# AT32F407xx register map
Vendor: Keil; Series: AT32F407; File version: 1.0
CPU: CM4 r0p1, little endian, no MPU, FPU, 4 interrupt priority bits
Registers are 32-bit, read-write, reset 0x0 unless marked. A register's access mark holds for its fields unless they carry their own. Offsets are from the block's base; [hi:lo] are bit positions.

## Ethernet_PTP — Ethernet: Precision time protocol
Base 0x40028700
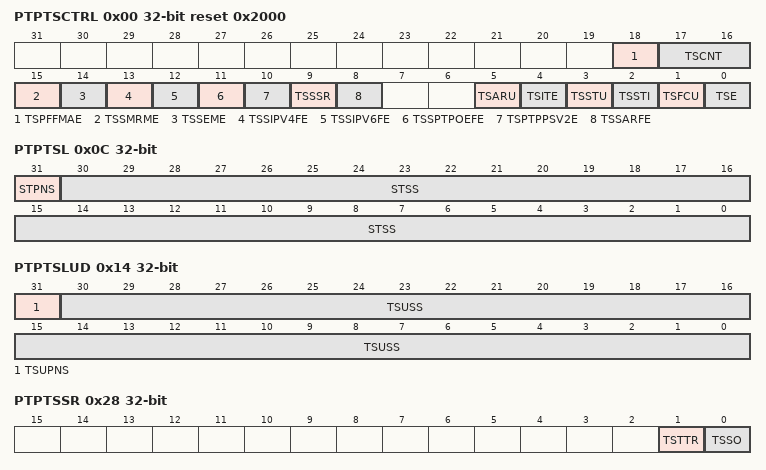
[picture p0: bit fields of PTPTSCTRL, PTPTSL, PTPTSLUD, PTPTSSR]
0x00 PTPTSCTRL reset 0x2000 — Ethernet PTP time stamp control register
  [18] TSPFFMAE — Time stamp PTP frame filtering MAC address enable
  [17:16] TSCNT — Time stamp clock node type
  [15] TSSMRME — Time stamp snapshot for message relevant to master enable
  [14] TSSEME — Time stamp snapshot for event message enable
  [13] TSSIPV4FE — Time stamp snapshot for IPv4 frames enable
  [12] TSSIPV6FE — Time stamp snapshot for IPv6 frames enable
  [11] TSSPTPOEFE — Time stamp snapshot for PTP over ethernet frames enable
  [10] TSPTPPSV2E — Time stamp PTP packet snooping for version2 format enable
  [9] TSSSR — Time stamp subsecond rollover: digital or binary rollover control
  [8] TSSARFE — Time stamp snapshot for all received frames enable
  [5] TSARU — Time stamp addend register update
  [4] TSITE — Time stamp interrupt trigger enable
  [3] TSSTU — Time stamp system time update
  [2] TSSTI — Time stamp system time initialize
  [1] TSFCU — Time stamp fine or coarse update
  [0] TSE — Time stamp enable
0x04 PTPSSINC — Ethernet PTP subsecond increment register
  [7:0] STSINC — System time subsecond increment
0x08 PTPTSH ro — Ethernet PTP time stamp high register
  [31:0] STS — System time second
0x0C PTPTSL ro — Ethernet PTP time stamp low register
  [31] STPNS — System time positive or negative sign
  [30:0] STSS — System time subseconds
0x10 PTPTSHUD — Ethernet PTP time stamp high update register
  [31:0] TSUS — Time stamp update second
0x14 PTPTSLUD — Ethernet PTP time stamp low update register
  [31] TSUPNS — Time stamp update positive or negative sign
  [30:0] TSUSS — Time stamp update subseconds
0x18 PTPTSAD — Ethernet PTP time stamp addend register
  [31:0] TSA — Time stamp addend
0x1C PTPTTH — Ethernet PTP target time high register
  [31:0] TTSH — Target time stamp high
0x20 PTPTTL — Ethernet PTP target time low register
  [31:0] TTSL — Target time stamp low
0x28 PTPTSSR ro — Ethernet PTP time stamp status register
  [1] TSTTR — Time stamp target time reached
  [0] TSSO — Time stamp second overflow
0x2C PTPPPSCR ro — Ethernet PTP PPS control register
  [3:0] PPSFREQ — PPS frequency selection

## ETHERNET_DMA — Ethernet: DMA controller operation
Base 0x40029000
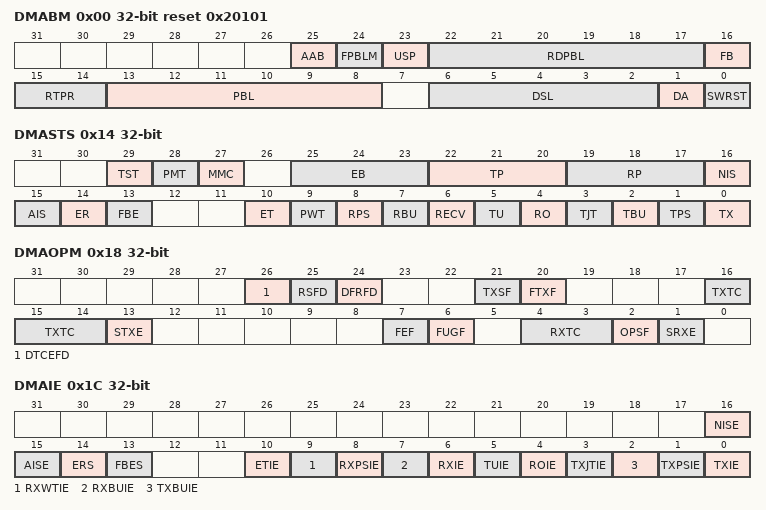
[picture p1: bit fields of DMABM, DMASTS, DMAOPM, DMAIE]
0x00 DMABM reset 0x20101 — Ethernet DMA bus mode register
  [25] AAB — Address-aligned beats
  [24] FPBLM — 8xPBL mode
  [23] USP — Use separate PBL
  [22:17] RDPBL — Rx DMA PBL
  [16] FB — Fixed burst
  [15:14] RTPR — Rx Tx priority ratio
  [13:8] PBL — Programmable burst length
  [6:2] DSL — Descriptor skip length
  [1] DA — DMA Arbitration
  [0] SWRST — Software reset
0x04 DMATPD — Ethernet DMA transmit poll demand register
  [31:0] TPD — Transmit poll demand
0x08 DMARPD — EHERNET DMA receive poll demand register
  [31:0] RPD — Receive poll demand
0x0C DMARDLADDR — Ethernet DMA receive descriptor list address register
  [31:0] SRL — Start of receive list
0x10 DMATDLADDR — Ethernet DMA transmit descriptor list address register
  [31:0] STL — Start of transmit list
0x14 DMASTS — Ethernet DMA status register
  [29] TST ro — Time stamp trigger status
  [28] PMT ro — PMT status
  [27] MMC ro — MMC status
  [25:23] EB ro — Error bits status
  [22:20] TP ro — Transmit process state
  [19:17] RP ro — Receive process state
  [16] NIS — Normal interrupt summary
  [15] AIS — Abnormal interrupt summary
  [14] ER — Early receive status
  [13] FBE — Fatal bus error status
  [10] ET — Early transmit status
  [9] PWT — Receive watchdog timeout status
  [8] RPS — Receive process stopped status
  [7] RBU — Receive buffer unavailable status
  [6] RECV — Receive status
  [5] TU — Transmit underflow status
  [4] RO — Receive overflow status
  [3] TJT — Transmit jabber timeout status
  [2] TBU — Transmit buffer unavailable status
  [1] TPS — Transmit process stopped status
  [0] TX — Transmit status
0x18 DMAOPM — Ethernet DMA operation mode register
  [26] DTCEFD
  [25] RSFD
  [24] DFRFD
  [21] TXSF
  [20] FTXF
  [16:14] TXTC — TTC
  [13] STXE
  [7] FEF
  [6] FUGF
  [4:3] RXTC
  [2] OPSF
  [1] SRXE — Start/stop receive
0x1C DMAIE — Ethernet DMA interrupt enable register
  [16] NISE — Normal interrupt summary enable
  [15] AISE — Abnormal interrupt summary enable
  [14] ERS — Early receive interrupt enable
  [13] FBES — Fatal bus error interrupt enable
  [10] ETIE — Early transmit interrupt enable
  [9] RXWTIE — receive watchdog timeout interrupt enable
  [8] RXPSIE — Receive process stopped interrupt enable
  [7] RXBUIE — Receive buffer unavailable interrupt enable
  [6] RXIE — Receive interrupt enable
  [5] TUIE — Underflow interrupt enable
  [4] ROIE — Overflow interrupt enable
  [3] TXJTIE — Transmit jabber timeout interrupt enable
  [2] TXBUIE — Transmit buffer unavailable interrupt enable
  [1] TXPSIE — Transmit process stopped interrupt enable
  [0] TXIE — Transmit interrupt enable
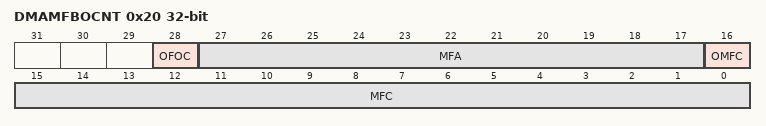
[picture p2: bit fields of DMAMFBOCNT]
0x20 DMAMFBOCNT ro — Ethernet DMA missed frame and buffer overflow counter register
  [28] OFOC — Overflow bit for FIFO overflow counter
  [27:17] MFA — Missed frames by the application
  [16] OMFC — Overflow bit for missed frame counter
  [15:0] MFC — Missed frames by the controller
0x48 DMACTD ro — Ethernet DMA current host transmit descriptor register
  [31:0] HTDAP — Host transmit descriptor address pointer
0x4C DMACRD ro — Ethernet DMA current host receive descriptor register
  [31:0] HRDAP — Host receive descriptor address pointer
0x50 DMACTBADDR ro — Ethernet DMA current host transmit buffer address register
  [31:0] HTBAP — Host transmit buffer address pointer
0x54 DMACRBADDR ro — Ethernet DMA current host receive buffer address register
  [31:0] HRBAP — Host receive buffer address pointer
